# DDPA_K3_DDPA_00580000h register map
Vendor: Texas Instruments
Peripheral module from a debugger description file (folder AM275x).
Registers are 32-bit, access not given, reset 0x0 unless marked. A register's access mark holds for its fields unless they carry their own. Offsets are as the file gives them; lines under a group give offsets from that group; [hi:lo] are bit positions; {n}, {i} and the like mark numbered series; 'fields as' and 'values as' point back to an identical list; <NAME> marks a mode.

## k3_ddpa
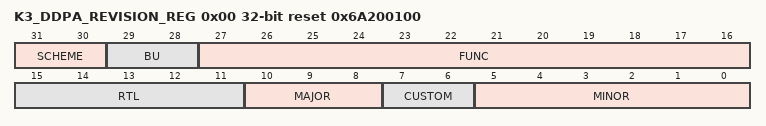
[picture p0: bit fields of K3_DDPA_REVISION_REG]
0x00 K3_DDPA_REVISION_REG ro reset 0x6A200100 — K3_DDPA PID
  [31:30] SCHEME — Used to distinguish between old scheme and new scheme. Spare bit to encode future schemes Reset Source: rstn_mod_g_rst_n
  [29:28] BU — BU indicatorDSPS ==> 0x0 WTBU ==> 0x1 Processors ==> 0x2 Reset Source: rstn_mod_g_rst_n
  [27:16] FUNC — Function indicates a software compatible module family. If there is no level of software compatibility a new FUNC number, and hence PID, should be assigned. Reset Source: rstn_mod_g_rst_n
  [15:11] RTL — RTL Version. R as described in PDR with additional clarifications and definitions below. Must be easily ECO-able or controlled during fabrication. Ideally through a top level metal mask or e-fuse. This number is maintained/owned by IP design owner. RTL follows a numbering such as X.Y.R.Z which are explained in this table. R changes ONLY when: (1) PDS uploads occur which may have been due to spec changes (2) Bug fixes occur (3) Resets to '0' when X or Y changes. Design team has an internal 'Z' (customer invisible) number which increments on every drop that happens due to DV and RTL updates. Z resets to 0 when R increments. Reset Source: rstn_mod_g_rst_n
  [10:8] MAJOR — Major Revision. X as described in PDR with additional clarifications/definitions below. This number is owned/maintained by IP specification owner. X is part of IP numbering X.Y.R.Z.X changes ONLY when: (1) There is a major feature addition. An example would be adding Initiator Mode to Utopia Level2. The Func field (or Class/Type in old PID format) will remain the same. X does NOT change due to: (1) Bug fixes (2) Change in feature parameters. Reset Source: rstn_mod_g_rst_n
  [7:6] CUSTOM — Indicates a special version for a particular device. Consequence of use may avoid use of standard Chip Support Library (CSL) / Drivers. 0 if non-custom. Reset Source: rstn_mod_g_rst_n
  [5:0] MINOR — Minor Revision. Y as described in PDR with additional clarifications/definitions below. This number is owned/maintained by IP specification owner. Y changes ONLY when: (1) Features are scaled (up or down). Flexibility exists in that this feature scalability may either be represented in the Y change or a specific register in the IP that indicates which features are exactly available. (2) When feature creeps from Is-Not list to Is list. But this may not be the case once it sees silicon - in which case X will change. Y does NOT change due to: (1) Bug fixes (2) Typos or clarifications (3) major functional/feature change/addition/deletion. Instead these changes may be reflected via R, S, X as applicable. Spec owner maintains a customer-invisible number 'S' which changes due to: (1) Typos/clarifications (2) Bug documentation. Note that this bug is not due to a spec change but due to implementation. Nevertheless, the spec tracks the IP bugs. An RTL release (say for silicon PG1.1) that occurs due to bug fix should document the corresponding spec number (X.Y.S) in its release notes. Reset Source: rstn_mod_g_rst_n
0x04 K3_DDPA_DEBUGSS_INHIBITSLEEP_REQ_STAT ro — Status bits showing the lel of INHIBIT_SLEEP request inputs from the Power-AP module into DDPA
  [31:0] PORT — Status bits showing the level of the Inhibit_sleep request inputs from Power-AP into DDPA. Reset Source: rstn_mod_g_rst_n
0x14 K3_DDPA_DEBUGSS_INHIBITSLEEP_REQ_SET — Interrupt RAW event status and set for interrupt INHIBIT_SLEEP per AP-power port
  [31:0] PORT — Write-operation: 0: Nothing happens. 1: Causes the interrupt flag to be set. Used to manually force/drive an interrupt pending event. Reads: This MMR reflects the RAW status of the interrupt flag due to inhibitsleep request events by any of the 32 power-AP ports. 0: The values of the corresponding power-AP port in MMRs DEBUGSS_INHIBIT_SLEEP_REQ_STAT and DEBUGSS_INHIBIT_SLEEP_REQ_SET/CLR are equal. 1: The values of the corresponding power-AP port in MMRs DEBUGSS_INHIBIT_SLEEP_REQ_STAT and DEBUGSS_INHIBIT_SLEEP_REQ_SET/CLR are different Reset Source: rstn_mod_g_rst_n (access R/W1TS)
0x24 K3_DDPA_DEBUGSS_INHIBITSLEEP_REQ_CLR — Enabled interrupt event status and clear for interrupt INHIBIT_SLEEP per AP-power port.
  [31:0] PORT — Write-operation: 0: Nothing happens. 1: Causes the bit to be cleared. Reads:This MMR reflects the MASKED status of the interrupt flag due to inhibitsleep request events by any of the 32 power-AP ports. The mask source is DDPA_INT_EN_SET/CLR. 0: The values of the corresponding power-AP port in MMRs DEBUGSS_INHIBIT_SLEEP_REQ_STAT and DEBUGSS_INHIBIT_SLEEP_REQ_SET/CLR are equal. 1: The values of the corresponding power-AP port in MMRs DEBUGSS_INHIBIT_SLEEP_REQ_STAT and DEBUGSS_INHIBIT_SLEEP_REQ_SET/CLR are different. Reset Source: rstn_mod_g_rst_n (access R/W1TC)
0x34 K3_DDPA_DEBUGSS_INHIBITSLEEP_ACK_SET — Interrupt RAW event status and set for interrupt INHIBIT_SLEEP per AP-power port
  [31:0] PORT — Write-operation: 0: Nothing happens. 1: Set the inhibit sleep acknowledgement Reset Source: rstn_mod_g_rst_n (access R/W1TS)
0x44 K3_DDPA_DEBUGSS_INHIBITSLEEP_ACK_CLR — Enabled interrupt event status and clear for interrupt INHIBIT_SLEEP per AP-power port.
  [31:0] PORT — Write-operation: 0: Nothing happens. 1: clears the inhibit sleep acknowledgement Reset Source: rstn_mod_g_rst_n (access R/W1TC)
0x54 K3_DDPA_DEBUGSS_FORCEACTIVE_REQ_STAT ro — Status bits showing the lel of FORCE_ACTIVE request inputs from the Power-AP module into DDPA
  [31:0] PORT — Status bits showing the level of the FORCE_ACTIVE request inputs from Power-AP into DDPA. Reset Source: rstn_mod_g_rst_n
0x64 K3_DDPA_DEBUGSS_FORCEACTIVE_REQ_SET — Interrupt RAW event status and set for interrupt FORCE_ACTIVE per AP-power port
  [31:0] PORT — Write-operation: 0: Nothing happens. 1: Causes the interrupt flag to be set. Used to manually force/drive an interrupt pending event. Reads: This MMR reflects the RAW status of the interrupt flag due to inhibitsleep request events by any of the 32 power-AP ports. 0: The values of the corresponding power-AP port in MMRs DEBUGSS_FORCE_ACTIVE_REQ_STAT and DEBUGSS_FORCE_ACTIVE_REQ_SET/CLR are equal. 1: The values of the corresponding power-AP port in MMRs DEBUGSS_FORCE_ACTIVE_REQ_STAT and DEBUGSS_FORCE_ACTIVE_REQ_SET/CLR are different Reset Source: rstn_mod_g_rst_n (access R/W1TS)
0x74 K3_DDPA_DEBUGSS_FORCEACTIVE_REQ_CLR — Enabled interrupt event status and clear for interrupt FORCE_ACTIVE per AP-power port.
  [31:0] PORT — Write-operation: 0: Nothing happens. 1: Causes the bit to be cleared. Reads:This MMR reflects the MASKED status of the interrupt flag due to inhibitsleep request events by any of the 32 power-AP ports. The mask source is DDPA_INT_EN_SET/CLR. 0: The values of the corresponding power-AP port in MMRs DEBUGSS_FORCE_ACTIVE_REQ_STAT and DEBUGSS_FORCE_ACTIVE_REQ_SET/CLR are equal. 1: The values of the corresponding power-AP port in MMRs DEBUGSS_FORCE_ACTIVE_REQ_STAT and DEBUGSS_FORCE_ACTIVE_REQ_SET/CLR are different. Reset Source: rstn_mod_g_rst_n (access R/W1TC)
0x84 K3_DDPA_DEBUGSS_FORCEACTIVE_ACK_SET — Interrupt RAW event status and set for interrupt FORCE_ACTIVE per AP-power port
  [31:0] PORT — Write-operation: 0: Nothing happens. 1: Set the force active acknowledgement Reset Source: rstn_mod_g_rst_n (access R/W1TS)
0x94 K3_DDPA_DEBUGSS_FORCEACTIVE_ACK_CLR — Enabled interrupt event status and clear for interrupt FORCE_ACTIVE per AP-power port.
  [31:0] PORT — Write-operation: 0: Nothing happens. 1: clears the force active acknowledgement Reset Source: rstn_mod_g_rst_n (access R/W1TC)
0xA4 K3_DDPA_DEBUGSS_BLOCKRESET_REQ_STAT ro — Status bits showing the lel of BLOCK_RESET request inputs from the Power-AP module into DDPA
  [31:0] PORT — Status bits showing the level of the BLOCK_RESET request inputs from Power-AP into DDPA. Reset Source: rstn_mod_g_rst_n
0xB4 K3_DDPA_DEBUGSS_BLOCKRESET_REQ_SET — Interrupt RAW event status and set for interrupt BLOCK_RESET per AP-power port
  [31:0] PORT — Write-operation: 0: Nothing happens. 1: Causes the interrupt flag to be set. Used to manually force/drive an interrupt pending event. Reads: This MMR reflects the RAW status of the interrupt flag due to inhibitsleep request events by any of the 32 power-AP ports. 0: The values of the corresponding power-AP port in MMRs DEBUGSS_BLOCK_RESET_REQ_STAT and DEBUGSS_BLOCK_RESET_REQ_SET/CLR are equal. 1: The values of the corresponding power-AP port in MMRs DEBUGSS_BLOCK_RESET_REQ_STAT and DEBUGSS_BLOCK_RESET_REQ_SET/CLR are different Reset Source: rstn_mod_g_rst_n (access R/W1TS)
0xC4 K3_DDPA_DEBUGSS_BLOCKRESET_REQ_CLR — Enabled interrupt event status and clear for interrupt BLOCK_RESET per AP-power port.
  [31:0] PORT — Write-operation: 0: Nothing happens. 1: Causes the bit to be cleared. Reads:This MMR reflects the MASKED status of the interrupt flag due to inhibitsleep request events by any of the 32 power-AP ports. The mask source is DDPA_INT_EN_SET/CLR. 0: The values of the corresponding power-AP port in MMRs DEBUGSS_BLOCK_RESET_REQ_STAT and DEBUGSS_BLOCK_RESET_REQ_SET/CLR are equal. 1: The values of the corresponding power-AP port in MMRs DEBUGSS_BLOCK_RESET_REQ_STAT and DEBUGSS_BLOCK_RESET_REQ_SET/CLR are different. Reset Source: rstn_mod_g_rst_n (access R/W1TC)
0xD4 K3_DDPA_DEBUGSS_ASSERTRESET_REQ_STAT ro — Status bits showing the lel of ASSERT_RESET request inputs from the Power-AP module into DDPA
  [31:0] PORT — Status bits showing the level of the ASSERT_RESET request inputs from Power-AP into DDPA. Reset Source: rstn_mod_g_rst_n
0xE4 K3_DDPA_DEBUGSS_ASSERTRESET_REQ_SET — Interrupt RAW event status and set for interrupt ASSERT_RESET per AP-power port
  [31:0] PORT — Write-operation: 0: Nothing happens. 1: Causes the interrupt flag to be set. Used to manually force/drive an interrupt pending event. Reads: This MMR reflects the RAW status of the interrupt flag due to inhibitsleep request events by any of the 32 power-AP ports. 0: The values of the corresponding power-AP port in MMRs DEBUGSS_ASSERT_RESET_REQ_STAT and DEBUGSS_ASSERT_RESET_REQ_SET/CLR are equal. 1: The values of the corresponding power-AP port in MMRs DEBUGSS_ASSERT_RESET_REQ_STAT and DEBUGSS_ASSERT_RESET_REQ_SET/CLR are different Reset Source: rstn_mod_g_rst_n (access R/W1TS)
0xF4 K3_DDPA_DEBUGSS_ASSERTRESET_REQ_CLR — Enabled interrupt event status and clear for interrupt ASSERT_RESET per AP-power port.
  [31:0] PORT — Write-operation: 0: Nothing happens. 1: Causes the bit to be cleared. Reads:This MMR reflects the MASKED status of the interrupt flag due to inhibitsleep request events by any of the 32 power-AP ports. The mask source is DDPA_INT_EN_SET/CLR. 0: The values of the corresponding power-AP port in MMRs DEBUGSS_ASSERT_RESET_REQ_STAT and DEBUGSS_ASSERT_RESET_REQ_SET/CLR are equal. 1: The values of the corresponding power-AP port in MMRs DEBUGSS_ASSERT_RESET_REQ_STAT and DEBUGSS_ASSERT_RESET_REQ_SET/CLR are different. Reset Source: rstn_mod_g_rst_n (access R/W1TC)
0x104 K3_DDPA_PSC_INHIBITSLEEP_SET_j — MMR used to set to '1' the bit contents of PSC_INHIBIT_SLEEP_SET/CLR. INHIBIT_SLEEP req is asserted on the PSC interface
  [31:0] PORT — 0: Writing 0 to this field produces no effect. 1: Writing 1 to any of the bits in this field sets to '1' the corresponding bit in that field. Reset Source: rstn_mod_g_rst_n (access R/W1TS)
0x124 K3_DDPA_PSC_INHIBITSLEEP_CLR_j — MMR used to set to '0' the bit contents of PSC_INHIBIT_SLEEP_SET/CLR. INHIBIT_SLEEP req is de-asserted on the PSC interface
  [31:0] PORT — 0: Writing 0 to this field produces no effect. 1: Writing 1 to any of the bits in this field sets to '0' the corresponding bit in that field. Reset Source: rstn_mod_g_rst_n (access R/W1TC)
0x144 K3_DDPA_PSC_INHIBITSLEEP_STAT_j ro — Status bits showing the ACK for the INHIBIT_SLEEP request. This ACK is input to the DDPA on the PSC interface
  [31:0] PORT — Status bits showing the level of the INHIBIT_SLEEP request ACK inputs from PSC into DDPA. Reset Source: rstn_mod_g_rst_n
0x164 K3_DDPA_PSC_FORCEACTIVE_SET_j — MMR used to set to '1' the bit contents of PSC_FORCE_ACTIVE_SET/CLR. FORCE_ACTIVE req is asserted on the PSC interface
  fields as K3_DDPA_PSC_INHIBITSLEEP_SET_j
0x184 K3_DDPA_PSC_FORCEACTIVE_CLR_j — MMR used to set to '0' the bit contents of PSC_FORCE_ACTIVE_SET/CLR. FORCE_ACTIVE req is de-asserted on the PSC interface
  fields as K3_DDPA_PSC_INHIBITSLEEP_CLR_j
0x1A4 K3_DDPA_PSC_FORCEACTIVE_STAT_j ro — Status bits showing the ACK for the FORCE_ACTIVE request. This ACK is input to the DDPA on the PSC interface
  [31:0] PORT — Status bits showing the level of the FORCE_ACTIVE request ACK inputs from PSC into DDPA. Reset Source: rstn_mod_g_rst_n
0x1C4 K3_DDPA_PSC_BLOCKRESET_SET_j — MMR used to set to '1' the bit contents of PSC_BLOCK_RESET_SET/CLR. BLOCK_RESET req is asserted on the PSC interface
  fields as K3_DDPA_PSC_INHIBITSLEEP_SET_j
0x1E4 K3_DDPA_PSC_BLOCKRESET_CLR_j — MMR used to set to '0' the bit contents of PSC_BLOCK_RESET_SET/CLR. BLOCK_RESET req is de-asserted on the PSC interface
  fields as K3_DDPA_PSC_INHIBITSLEEP_CLR_j
0x204 K3_DDPA_PSC_ASSERTRESET_SET_j — MMR used to set to '1' the bit contents of PSC_ASSERT_RESET_SET/CLR. ASSERT_RESET req is asserted on the PSC interface
  fields as K3_DDPA_PSC_INHIBITSLEEP_SET_j
0x224 K3_DDPA_PSC_ASSERTRESET_CLR_j — MMR used to set to '0' the bit contents of PSC_ASSERT_RESET_SET/CLR. ASSERT_RESET req is de-asserted on the PSC interface
  fields as K3_DDPA_PSC_INHIBITSLEEP_CLR_j
0x244 K3_DDPA_BYPASS_OVERRIDE rw — MMR used to enable/disable the DMSC firmware bypass
  [0] PORT — Enable/Disable the DMSC firmware bypass 0: Disable 1:Enable Reset Source: rstn_mod_g_rst_n
0x248 K3_DDPA_INT_EN_SET — MMR used to set to '1' the bit contents of DDPA_INT_EN_SET/CLR.
  fields as K3_DDPA_PSC_INHIBITSLEEP_SET_j
0x258 K3_DDPA_INT_EN_CLR — MMR used to set to '0' the bit contents of DDPA_INT_EN_SET/CLR.
  fields as K3_DDPA_PSC_INHIBITSLEEP_CLR_j
